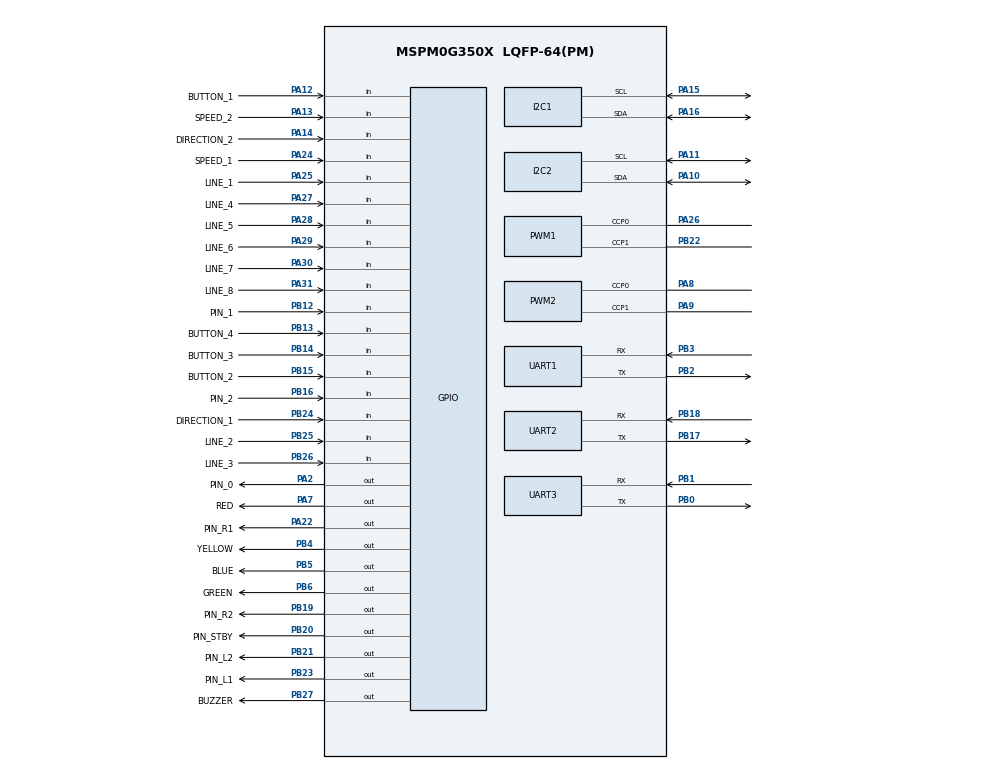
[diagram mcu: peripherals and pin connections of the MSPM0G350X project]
/**
 * @cliArgs --device "MSPM0G350X" --part "Default" --package "LQFP-64(PM)" --product "mspm0_sdk@2.08.00.02"
 * @versions {"tool":"1.25.0+4268"}
 */

/**
 * Import the modules used in this configuration.
 */
const GPIO   = scripting.addModule("/ti/driverlib/GPIO", {}, false);
const GPIO1  = GPIO.addInstance();
const GPIO2  = GPIO.addInstance();
const GPIO3  = GPIO.addInstance();
const GPIO4  = GPIO.addInstance();
const GPIO5  = GPIO.addInstance();
const GPIO6  = GPIO.addInstance();
const GPIO7  = GPIO.addInstance();
const GPIO8  = GPIO.addInstance();
const I2C    = scripting.addModule("/ti/driverlib/I2C", {}, false);
const I2C1   = I2C.addInstance();
const I2C2   = I2C.addInstance();
const PWM    = scripting.addModule("/ti/driverlib/PWM", {}, false);
const PWM1   = PWM.addInstance();
const PWM2   = PWM.addInstance();
const SYSCTL = scripting.addModule("/ti/driverlib/SYSCTL");
const TIMER  = scripting.addModule("/ti/driverlib/TIMER", {}, false);
const TIMER1 = TIMER.addInstance();
const UART   = scripting.addModule("/ti/driverlib/UART", {}, false);
const UART1  = UART.addInstance();
const UART2  = UART.addInstance();
const UART3  = UART.addInstance();

/**
 * Write custom configuration values to the imported modules.
 */
GPIO1.$name                              = "GPIO_MOTOR";
GPIO1.associatedPins.create(5);
GPIO1.associatedPins[0].$name            = "PIN_L1";
GPIO1.associatedPins[0].pin.$assign      = "PB23";
GPIO1.associatedPins[1].$name            = "PIN_L2";
GPIO1.associatedPins[1].pin.$assign      = "PB21";
GPIO1.associatedPins[2].$name            = "PIN_R1";
GPIO1.associatedPins[2].ioStructure      = "SD";
GPIO1.associatedPins[2].pin.$assign      = "PA22";
GPIO1.associatedPins[3].$name            = "PIN_R2";
GPIO1.associatedPins[3].ioStructure      = "SD";
GPIO1.associatedPins[3].pin.$assign      = "PB19";
GPIO1.associatedPins[4].$name            = "PIN_STBY";
GPIO1.associatedPins[4].internalResistor = "PULL_UP";
GPIO1.associatedPins[4].pin.$assign      = "PB20";

const Board = scripting.addModule("/ti/driverlib/Board", {}, false);

GPIO2.$name                              = "GPIO_BUTTON";
GPIO2.associatedPins.create(4);
GPIO2.associatedPins[0].internalResistor = "PULL_UP";
GPIO2.associatedPins[0].$name            = "BUTTON_1";
GPIO2.associatedPins[0].direction        = "INPUT";
GPIO2.associatedPins[0].pin.$assign      = "PA12";
GPIO2.associatedPins[1].$name            = "BUTTON_2";
GPIO2.associatedPins[1].direction        = "INPUT";
GPIO2.associatedPins[1].internalResistor = "PULL_UP";
GPIO2.associatedPins[1].pin.$assign      = "PB15";
GPIO2.associatedPins[2].$name            = "BUTTON_3";
GPIO2.associatedPins[2].direction        = "INPUT";
GPIO2.associatedPins[2].internalResistor = "PULL_UP";
GPIO2.associatedPins[2].pin.$assign      = "PB14";
GPIO2.associatedPins[3].$name            = "BUTTON_4";
GPIO2.associatedPins[3].direction        = "INPUT";
GPIO2.associatedPins[3].internalResistor = "PULL_UP";
GPIO2.associatedPins[3].pin.$assign      = "PB13";

GPIO3.$name                         = "GPIO_QEI";
GPIO3.associatedPins.create(4);
GPIO3.associatedPins[0].$name       = "SPEED_1";
GPIO3.associatedPins[0].direction   = "INPUT";
GPIO3.associatedPins[0].interruptEn = true;
GPIO3.associatedPins[0].polarity    = "RISE_FALL";
GPIO3.associatedPins[0].pin.$assign = "PA24";
GPIO3.associatedPins[1].$name       = "DIRECTION_1";
GPIO3.associatedPins[1].direction   = "INPUT";
GPIO3.associatedPins[1].pin.$assign = "PB24";
GPIO3.associatedPins[2].$name       = "SPEED_2";
GPIO3.associatedPins[2].direction   = "INPUT";
GPIO3.associatedPins[2].interruptEn = true;
GPIO3.associatedPins[2].polarity    = "RISE_FALL";
GPIO3.associatedPins[2].pin.$assign = "PA13";
GPIO3.associatedPins[3].$name       = "DIRECTION_2";
GPIO3.associatedPins[3].direction   = "INPUT";
GPIO3.associatedPins[3].pin.$assign = "PA14";

GPIO4.$name                         = "GPIO_LED";
GPIO4.associatedPins.create(4);
GPIO4.associatedPins[0].$name       = "RED";
GPIO4.associatedPins[0].pin.$assign = "PA7";
GPIO4.associatedPins[1].$name       = "YELLOW";
GPIO4.associatedPins[1].pin.$assign = "PB4";
GPIO4.associatedPins[2].$name       = "BLUE";
GPIO4.associatedPins[2].pin.$assign = "PB5";
GPIO4.associatedPins[3].$name       = "GREEN";
GPIO4.associatedPins[3].pin.$assign = "PB6";

GPIO5.$name                         = "GPIO_LINE";
GPIO5.associatedPins.create(8);
GPIO5.associatedPins[0].$name       = "LINE_1";
GPIO5.associatedPins[0].direction   = "INPUT";
GPIO5.associatedPins[0].pin.$assign = "PA25";
GPIO5.associatedPins[1].$name       = "LINE_2";
GPIO5.associatedPins[1].direction   = "INPUT";
GPIO5.associatedPins[1].pin.$assign = "PB25";
GPIO5.associatedPins[2].$name       = "LINE_3";
GPIO5.associatedPins[2].direction   = "INPUT";
GPIO5.associatedPins[2].pin.$assign = "PB26";
GPIO5.associatedPins[3].$name       = "LINE_4";
GPIO5.associatedPins[3].direction   = "INPUT";
GPIO5.associatedPins[3].pin.$assign = "PA27";
GPIO5.associatedPins[4].$name       = "LINE_5";
GPIO5.associatedPins[4].direction   = "INPUT";
GPIO5.associatedPins[4].pin.$assign = "PA28";
GPIO5.associatedPins[5].$name       = "LINE_6";
GPIO5.associatedPins[5].direction   = "INPUT";
GPIO5.associatedPins[5].pin.$assign = "PA29";
GPIO5.associatedPins[6].$name       = "LINE_7";
GPIO5.associatedPins[6].direction   = "INPUT";
GPIO5.associatedPins[6].pin.$assign = "PA30";
GPIO5.associatedPins[7].$name       = "LINE_8";
GPIO5.associatedPins[7].direction   = "INPUT";
GPIO5.associatedPins[7].pin.$assign = "PA31";

GPIO6.$name                         = "GPIO_BUZZER";
GPIO6.associatedPins[0].$name       = "BUZZER";
GPIO6.associatedPins[0].pin.$assign = "PB27";

GPIO7.$name                         = "GPIO_PS";
GPIO7.associatedPins.create(2);
GPIO7.associatedPins[0].$name       = "PIN_1";
GPIO7.associatedPins[0].direction   = "INPUT";
GPIO7.associatedPins[0].pin.$assign = "PB12";
GPIO7.associatedPins[1].$name       = "PIN_2";
GPIO7.associatedPins[1].direction   = "INPUT";
GPIO7.associatedPins[1].pin.$assign = "PB16";

GPIO8.$name                         = "GPIO_RELAY";
GPIO8.associatedPins[0].$name       = "PIN_0";
GPIO8.associatedPins[0].pin.$assign = "PA2";

I2C1.$name                             = "I2C_OLED";
I2C1.basicEnableController             = true;
I2C1.basicControllerStandardBusSpeed   = "Fast";
I2C1.peripheral.sdaPin.$assign         = "PA16";
I2C1.peripheral.sclPin.$assign         = "PA15";
I2C1.sdaPinConfig.hideOutputInversion  = scripting.forceWrite(false);
I2C1.sdaPinConfig.onlyInternalResistor = scripting.forceWrite(false);
I2C1.sdaPinConfig.passedPeripheralType = scripting.forceWrite("Digital");
I2C1.sdaPinConfig.$name                = "ti_driverlib_gpio_GPIOPinGeneric3";
I2C1.sdaPinConfig.enableConfig         = true;
I2C1.sclPinConfig.hideOutputInversion  = scripting.forceWrite(false);
I2C1.sclPinConfig.onlyInternalResistor = scripting.forceWrite(false);
I2C1.sclPinConfig.passedPeripheralType = scripting.forceWrite("Digital");
I2C1.sclPinConfig.$name                = "ti_driverlib_gpio_GPIOPinGeneric4";
I2C1.sclPinConfig.enableConfig         = true;

I2C2.$name                             = "I2C_GYRO";
I2C2.peripheral.$assign                = "I2C0";
I2C2.peripheral.sdaPin.$assign         = "PA10";
I2C2.peripheral.sclPin.$assign         = "PA11";
I2C2.sdaPinConfig.hideOutputInversion  = scripting.forceWrite(false);
I2C2.sdaPinConfig.onlyInternalResistor = scripting.forceWrite(false);
I2C2.sdaPinConfig.passedPeripheralType = scripting.forceWrite("Digital");
I2C2.sdaPinConfig.$name                = "ti_driverlib_gpio_GPIOPinGeneric0";
I2C2.sclPinConfig.hideOutputInversion  = scripting.forceWrite(false);
I2C2.sclPinConfig.onlyInternalResistor = scripting.forceWrite(false);
I2C2.sclPinConfig.passedPeripheralType = scripting.forceWrite("Digital");
I2C2.sclPinConfig.$name                = "ti_driverlib_gpio_GPIOPinGeneric7";

PWM1.$name                              = "Motor";
PWM1.timerStartTimer                    = true;
PWM1.timerCount                         = 3200;
PWM1.peripheral.$assign                 = "TIMG8";
PWM1.peripheral.ccp0Pin.$assign         = "PA26";
PWM1.peripheral.ccp1Pin.$assign         = "PB22";
PWM1.PWM_CHANNEL_0.$name                = "ti_driverlib_pwm_PWMTimerCC1";
PWM1.PWM_CHANNEL_0.dutyCycle            = 15;
PWM1.PWM_CHANNEL_1.$name                = "ti_driverlib_pwm_PWMTimerCC2";
PWM1.ccp0PinConfig.direction            = scripting.forceWrite("OUTPUT");
PWM1.ccp0PinConfig.hideOutputInversion  = scripting.forceWrite(false);
PWM1.ccp0PinConfig.onlyInternalResistor = scripting.forceWrite(false);
PWM1.ccp0PinConfig.passedPeripheralType = scripting.forceWrite("Digital");
PWM1.ccp0PinConfig.$name                = "ti_driverlib_gpio_GPIOPinGeneric1";
PWM1.ccp1PinConfig.direction            = scripting.forceWrite("OUTPUT");
PWM1.ccp1PinConfig.hideOutputInversion  = scripting.forceWrite(false);
PWM1.ccp1PinConfig.onlyInternalResistor = scripting.forceWrite(false);
PWM1.ccp1PinConfig.passedPeripheralType = scripting.forceWrite("Digital");
PWM1.ccp1PinConfig.$name                = "ti_driverlib_gpio_GPIOPinGeneric2";

PWM2.$name                              = "Servo";
PWM2.timerStartTimer                    = true;
PWM2.timerCount                         = 40000;
PWM2.clockDivider                       = 8;
PWM2.peripheral.$assign                 = "TIMA0";
PWM2.peripheral.ccp0Pin.$assign         = "PA8";
PWM2.peripheral.ccp1Pin.$assign         = "PA9";
PWM2.PWM_CHANNEL_0.$name                = "ti_driverlib_pwm_PWMTimerCC0";
PWM2.PWM_CHANNEL_1.$name                = "ti_driverlib_pwm_PWMTimerCC3";
PWM2.ccp0PinConfig.direction            = scripting.forceWrite("OUTPUT");
PWM2.ccp0PinConfig.hideOutputInversion  = scripting.forceWrite(false);
PWM2.ccp0PinConfig.onlyInternalResistor = scripting.forceWrite(false);
PWM2.ccp0PinConfig.passedPeripheralType = scripting.forceWrite("Digital");
PWM2.ccp0PinConfig.$name                = "ti_driverlib_gpio_GPIOPinGeneric12";
PWM2.ccp1PinConfig.direction            = scripting.forceWrite("OUTPUT");
PWM2.ccp1PinConfig.hideOutputInversion  = scripting.forceWrite(false);
PWM2.ccp1PinConfig.onlyInternalResistor = scripting.forceWrite(false);
PWM2.ccp1PinConfig.passedPeripheralType = scripting.forceWrite("Digital");
PWM2.ccp1PinConfig.$name                = "ti_driverlib_gpio_GPIOPinGeneric13";

SYSCTL.forceDefaultClkConfig = true;

TIMER1.$name             = "TIMER_0";
TIMER1.timerClkDiv       = 8;
TIMER1.timerClkPrescale  = 200;
TIMER1.timerPeriod       = "2ms";
TIMER1.timerMode         = "PERIODIC";
TIMER1.interrupts        = ["ZERO"];
TIMER1.interruptPriority = "0";
TIMER1.timerStartTimer   = true;

UART1.enabledInterrupts                = ["RX"];
UART1.interruptPriority                = "1";
UART1.$name                            = "UART_OPENMV";
UART1.targetBaudRate                   = 115200;
UART1.peripheral.$assign               = "UART3";
UART1.peripheral.rxPin.$assign         = "PB3";
UART1.peripheral.txPin.$assign         = "PB2";
UART1.txPinConfig.direction            = scripting.forceWrite("OUTPUT");
UART1.txPinConfig.hideOutputInversion  = scripting.forceWrite(false);
UART1.txPinConfig.onlyInternalResistor = scripting.forceWrite(false);
UART1.txPinConfig.passedPeripheralType = scripting.forceWrite("Digital");
UART1.txPinConfig.$name                = "ti_driverlib_gpio_GPIOPinGeneric5";
UART1.rxPinConfig.hideOutputInversion  = scripting.forceWrite(false);
UART1.rxPinConfig.onlyInternalResistor = scripting.forceWrite(false);
UART1.rxPinConfig.passedPeripheralType = scripting.forceWrite("Digital");
UART1.rxPinConfig.$name                = "ti_driverlib_gpio_GPIOPinGeneric6";

UART2.$name                            = "UART_Bluetooth";
UART2.enabledInterrupts                = ["RX"];
UART2.targetBaudRate                   = 115200;
UART2.peripheral.$assign               = "UART2";
UART2.peripheral.rxPin.$assign         = "PB18";
UART2.peripheral.txPin.$assign         = "PB17";
UART2.txPinConfig.direction            = scripting.forceWrite("OUTPUT");
UART2.txPinConfig.hideOutputInversion  = scripting.forceWrite(false);
UART2.txPinConfig.onlyInternalResistor = scripting.forceWrite(false);
UART2.txPinConfig.passedPeripheralType = scripting.forceWrite("Digital");
UART2.txPinConfig.$name                = "ti_driverlib_gpio_GPIOPinGeneric9";
UART2.rxPinConfig.hideOutputInversion  = scripting.forceWrite(false);
UART2.rxPinConfig.onlyInternalResistor = scripting.forceWrite(false);
UART2.rxPinConfig.passedPeripheralType = scripting.forceWrite("Digital");
UART2.rxPinConfig.$name                = "ti_driverlib_gpio_GPIOPinGeneric10";

UART3.$name                            = "UART_openmv";
UART3.enabledInterrupts                = ["RX"];
UART3.interruptPriority                = "1";
UART3.peripheral.$assign               = "UART0";
UART3.peripheral.rxPin.$assign         = "PB1";
UART3.peripheral.txPin.$assign         = "PB0";
UART3.txPinConfig.direction            = scripting.forceWrite("OUTPUT");
UART3.txPinConfig.hideOutputInversion  = scripting.forceWrite(false);
UART3.txPinConfig.onlyInternalResistor = scripting.forceWrite(false);
UART3.txPinConfig.passedPeripheralType = scripting.forceWrite("Digital");
UART3.txPinConfig.$name                = "ti_driverlib_gpio_GPIOPinGeneric8";
UART3.rxPinConfig.hideOutputInversion  = scripting.forceWrite(false);
UART3.rxPinConfig.onlyInternalResistor = scripting.forceWrite(false);
UART3.rxPinConfig.passedPeripheralType = scripting.forceWrite("Digital");
UART3.rxPinConfig.$name                = "ti_driverlib_gpio_GPIOPinGeneric11";

/**
 * Pinmux solution for unlocked pins/peripherals. This ensures that minor changes to the automatic solver in a future
 * version of the tool will not impact the pinmux you originally saw.  These lines can be completely deleted in order to
 * re-solve from scratch.
 */
Board.peripheral.$suggestSolution          = "DEBUGSS";
Board.peripheral.swclkPin.$suggestSolution = "PA20";
Board.peripheral.swdioPin.$suggestSolution = "PA19";
I2C1.peripheral.$suggestSolution           = "I2C1";
SYSCTL.peripheral.$suggestSolution         = "SYSCTL";
TIMER1.peripheral.$suggestSolution         = "TIMA1";
